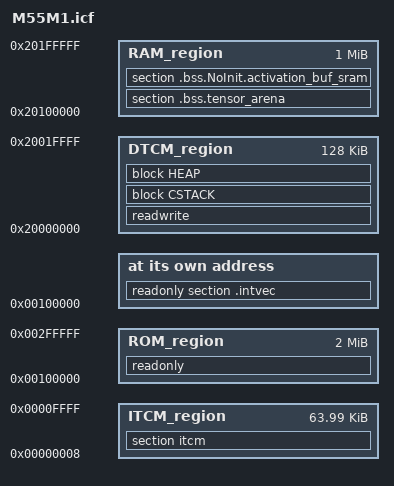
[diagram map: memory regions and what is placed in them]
/*###ICF### Section handled by ICF editor, don't touch! ****/
/*-Editor annotation file-*/
/* IcfEditorFile="$TOOLKIT_DIR$\config\ide\IcfEditor\cortex_v1_0.xml" */
/*-Specials-*/
define symbol __ICFEDIT_intvec_start__ = 0x00100000;

/*-Memory Regions-*/
define symbol __ICFEDIT_region_ITCM_start__ = 0x00000008;
define symbol __ICFEDIT_region_ITCM_end__   = 0x0000FFFF;
define symbol __ICFEDIT_region_ROM_start__  = 0x00100000;
define symbol __ICFEDIT_region_ROM_end__    = 0x002FFFFF;

define symbol __ICFEDIT_region_DTCM_start__ = 0x20000000;
define symbol __ICFEDIT_region_DTCM_end__   = 0x2001FFFF;
define symbol __ICFEDIT_region_RAM_start__  = 0x20100000;
define symbol __ICFEDIT_region_RAM_end__    = 0x201FFFFF;

/*-Sizes-*/
define symbol __ICFEDIT_size_cstack__ = 0x00002000;
define symbol __ICFEDIT_size_heap__   = 0x00004000;
/**** End of ICF editor section. ###ICF###*/

define memory mem with size = 4G;
define region ITCM_region = mem:[from __ICFEDIT_region_ITCM_start__ to __ICFEDIT_region_ITCM_end__];
define region ROM_region  = mem:[from __ICFEDIT_region_ROM_start__  to __ICFEDIT_region_ROM_end__ ];
define region DTCM_region = mem:[from __ICFEDIT_region_DTCM_start__ to __ICFEDIT_region_DTCM_end__];
define region RAM_region  = mem:[from __ICFEDIT_region_RAM_start__  to __ICFEDIT_region_RAM_end__ ];

define block CSTACK with alignment = 8, size = __ICFEDIT_size_cstack__ { };
define block HEAP   with alignment = 8, size = __ICFEDIT_size_heap__   { };

initialize by copy { readwrite, section itcm };

do not initialize  { section .noinit, section .bss.tensor_arena, section .bss.NoInit.activation_buf_sram };

place at address mem:__ICFEDIT_intvec_start__ { readonly section .intvec };

place in ITCM_region { section itcm };
place in ROM_region  { readonly } except { section itcm };
place in DTCM_region { readwrite, block CSTACK, block HEAP };
place in RAM_region  { section .bss.tensor_arena, section .bss.NoInit.activation_buf_sram };
